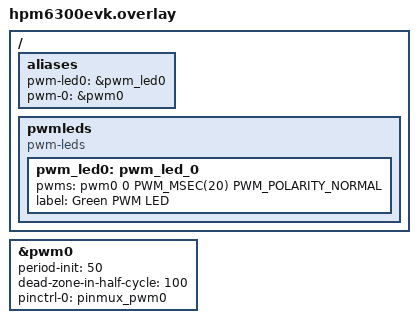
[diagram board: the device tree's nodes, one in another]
/*
 * Copyright 2026 HPMicro
 * SPDX-License-Identifier: Apache-2.0
 */

/ {
	aliases {
		pwm-led0 = &pwm_led0;
		pwm-0 = &pwm0;
	};

	pwmleds {
		compatible = "pwm-leds";
		pwm_led0: pwm_led_0 {
			pwms = <&pwm0 0 PWM_MSEC(20) PWM_POLARITY_NORMAL>;
			label = "Green PWM LED";
			status = "okay";
		};
	};
};

&pwm0 {
	status = "okay";
	period-init = <50>;
	dead-zone-in-half-cycle = <100>;
	pinctrl-0 = <&pinmux_pwm0>;
	pinctrl-names = "default";
};
